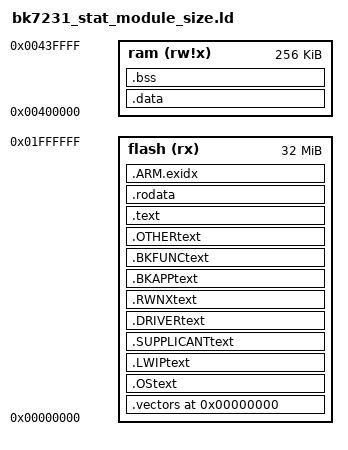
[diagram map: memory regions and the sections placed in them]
/* 
 * Script for GNU linker.
 * Describes layout of sections, location of stack.
 *
 * In this case vectors are at location 0 (reset @ 0x08)
 *
 * +------------+  0x00400000
 * data         |
 * end
 * |(heap)      |
 * .            .
 * .            .
 * |(heap limit)|
 *
 * |- - - - - - |
 * stack bottom    256k
 * +------------+  
 *
 * +------------+  0x0000000
 * |vectors     |
 * |            |
 * |------------+
 * |text        |  
 * |data        |
 * |            |  1024k
 * +------------+
 */


/* Split memory into area for vectors and ram */
MEMORY
{
	flash  (rx) : ORIGIN = 0x00000000, LENGTH = 32M
	ram   (rw!x): ORIGIN = 0x00400000, LENGTH = 256k
}

OUTPUT_FORMAT("elf32-littlearm", "elf32-littlearm", "elf32-littlearm")
OUTPUT_ARCH(arm)
ENTRY(_vector_start);
_vector_start = 0x00000000;

SECTIONS
{
/* vectors go to vectors region */
	. = 0x00000000;
	.vectors : 
	{ 
      KEEP(*(*.vectors))
	} > flash
	
	
	. = ALIGN(0x8);
	.OStext : 
	{
		beken378\os\mem_arch.o(.text)
		beken378\os\str_arch.o(.text)
		beken378\os\str_arch.o(.text.*)
		beken378\os\FreeRTOSv9.0.0\rtos_pub.o(.text)
		beken378\os\FreeRTOSv9.0.0\rtos_pub.o(.text.*)
		FreeRTOSv9.0.0\FreeRTOS\Source\croutine.o(.text)
		FreeRTOSv9.0.0\FreeRTOS\Source\croutine.o(.text.*)
		FreeRTOSv9.0.0\FreeRTOS\Source\event_groups.o(.text)
		FreeRTOSv9.0.0\FreeRTOS\Source\event_groups.o(.text.*)
		FreeRTOSv9.0.0\FreeRTOS\Source\list.o(.text)
		FreeRTOSv9.0.0\FreeRTOS\Source\list.o(.text.*)
		FreeRTOSv9.0.0\FreeRTOS\Source\queue.o(.text)
		FreeRTOSv9.0.0\FreeRTOS\Source\queue.o(.text.*)
		FreeRTOSv9.0.0\FreeRTOS\Source\tasks.o(.text)
		FreeRTOSv9.0.0\FreeRTOS\Source\tasks.o(.text.*)
		FreeRTOSv9.0.0\FreeRTOS\Source\timers.o(.text)
		FreeRTOSv9.0.0\FreeRTOS\Source\timers.o(.text.*)
		FreeRTOSv9.0.0\FreeRTOS\Source\portable\Keil\ARM968es\port.o(.text)
		FreeRTOSv9.0.0\FreeRTOS\Source\portable\Keil\ARM968es\port.o(.text.*)
		FreeRTOSv9.0.0\FreeRTOS\Source\portable\MemMang\heap_4.o(.text)
		FreeRTOSv9.0.0\FreeRTOS\Source\portable\MemMang\heap_4.o(.text.*)
	} > flash

	. = ALIGN(0x8);
	.LWIPtext : 
	{
		beken378\func\lwip_intf\lwip-2.0.2\port\ethernetif.o(.text)
		beken378\func\lwip_intf\lwip-2.0.2\port\net.o(.text)
		beken378\func\lwip_intf\lwip-2.0.2\port\sys_arch.o(.text)
		beken378\func\lwip_intf\lwip-2.0.2\src\api\api_lib.o(.text)
		beken378\func\lwip_intf\lwip-2.0.2\src\api\api_msg.o(.text)
		beken378\func\lwip_intf\lwip-2.0.2\src\api\err.o(.text)
		beken378\func\lwip_intf\lwip-2.0.2\src\api\netbuf.o(.text)
		beken378\func\lwip_intf\lwip-2.0.2\src\api\netdb.o(.text)
		beken378\func\lwip_intf\lwip-2.0.2\src\api\netifapi.o(.text)
		beken378\func\lwip_intf\lwip-2.0.2\src\api\sockets.o(.text)
		beken378\func\lwip_intf\lwip-2.0.2\src\api\tcpip.o(.text)
		beken378\func\lwip_intf\lwip-2.0.2\src\core\def.o(.text)
		beken378\func\lwip_intf\lwip-2.0.2\src\core\dns.o(.text)
		beken378\func\lwip_intf\lwip-2.0.2\src\core\inet_chksum.o(.text)
		beken378\func\lwip_intf\lwip-2.0.2\src\core\init.o(.text)
		beken378\func\lwip_intf\lwip-2.0.2\src\core\ip.o(.text)
		beken378\func\lwip_intf\lwip-2.0.2\src\core\mem.o(.text)
		beken378\func\lwip_intf\lwip-2.0.2\src\core\memp.o(.text)
		beken378\func\lwip_intf\lwip-2.0.2\src\core\netif.o(.text)
		beken378\func\lwip_intf\lwip-2.0.2\src\core\pbuf.o(.text)
		beken378\func\lwip_intf\lwip-2.0.2\src\core\raw.o(.text)
		beken378\func\lwip_intf\lwip-2.0.2\src\core\stats.o(.text)
		beken378\func\lwip_intf\lwip-2.0.2\src\core\sys.o(.text)
		beken378\func\lwip_intf\lwip-2.0.2\src\core\tcp.o(.text)
		beken378\func\lwip_intf\lwip-2.0.2\src\core\tcp_in.o(.text)
		beken378\func\lwip_intf\lwip-2.0.2\src\core\tcp_out.o(.text)
		beken378\func\lwip_intf\lwip-2.0.2\src\core\timeouts.o(.text)
		beken378\func\lwip_intf\lwip-2.0.2\src\core\udp.o(.text)
		beken378\func\lwip_intf\lwip-2.0.2\src\core\ipv4\autoip.o(.text)
		beken378\func\lwip_intf\lwip-2.0.2\src\core\ipv4\dhcp.o(.text)
		beken378\func\lwip_intf\lwip-2.0.2\src\core\ipv4\etharp.o(.text)
		beken378\func\lwip_intf\lwip-2.0.2\src\core\ipv4\icmp.o(.text)
		beken378\func\lwip_intf\lwip-2.0.2\src\core\ipv4\igmp.o(.text)
		beken378\func\lwip_intf\lwip-2.0.2\src\core\ipv4\ip4.o(.text)
		beken378\func\lwip_intf\lwip-2.0.2\src\core\ipv4\ip4_addr.o(.text)
		beken378\func\lwip_intf\lwip-2.0.2\src\core\ipv4\ip4_frag.o(.text)
		beken378\func\lwip_intf\lwip-2.0.2\src\core\ipv6\dhcp6.o(.text)
		beken378\func\lwip_intf\lwip-2.0.2\src\core\ipv6\ethip6.o(.text)
		beken378\func\lwip_intf\lwip-2.0.2\src\core\ipv6\icmp6.o(.text)
		beken378\func\lwip_intf\lwip-2.0.2\src\core\ipv6\inet6.o(.text)
		beken378\func\lwip_intf\lwip-2.0.2\src\core\ipv6\ip6.o(.text)
		beken378\func\lwip_intf\lwip-2.0.2\src\core\ipv6\ip6_addr.o(.text)
		beken378\func\lwip_intf\lwip-2.0.2\src\core\ipv6\ip6_frag.o(.text)
		beken378\func\lwip_intf\lwip-2.0.2\src\core\ipv6\mld6.o(.text)
		beken378\func\lwip_intf\lwip-2.0.2\src\core\ipv6\nd6.o(.text)
		beken378\func\lwip_intf\lwip-2.0.2\src\netif\ethernet.o(.text)
		beken378\func\lwip_intf\lwip-2.0.2\src\netif\lowpan6.o(.text)
		beken378\func\lwip_intf\lwip-2.0.2\src\netif\ppp\auth.o(.text)
		beken378\func\lwip_intf\lwip-2.0.2\src\netif\ppp\ccp.o(.text)
		beken378\func\lwip_intf\lwip-2.0.2\src\netif\ppp\chap-md5.o(.text)
		beken378\func\lwip_intf\lwip-2.0.2\src\netif\ppp\chap-new.o(.text)
		beken378\func\lwip_intf\lwip-2.0.2\src\netif\ppp\chap_ms.o(.text)
		beken378\func\lwip_intf\lwip-2.0.2\src\netif\ppp\demand.o(.text)
		beken378\func\lwip_intf\lwip-2.0.2\src\netif\ppp\eap.o(.text)
		beken378\func\lwip_intf\lwip-2.0.2\src\netif\ppp\ecp.o(.text)
		beken378\func\lwip_intf\lwip-2.0.2\src\netif\ppp\eui64.o(.text)
		beken378\func\lwip_intf\lwip-2.0.2\src\netif\ppp\fsm.o(.text)
		beken378\func\lwip_intf\lwip-2.0.2\src\netif\ppp\ipcp.o(.text)
		beken378\func\lwip_intf\lwip-2.0.2\src\netif\ppp\ipv6cp.o(.text)
		beken378\func\lwip_intf\lwip-2.0.2\src\netif\ppp\lcp.o(.text)
		beken378\func\lwip_intf\lwip-2.0.2\src\netif\ppp\magic.o(.text)
		beken378\func\lwip_intf\lwip-2.0.2\src\netif\ppp\mppe.o(.text)
		beken378\func\lwip_intf\lwip-2.0.2\src\netif\ppp\multilink.o(.text)
		beken378\func\lwip_intf\lwip-2.0.2\src\netif\ppp\ppp.o(.text)
		beken378\func\lwip_intf\lwip-2.0.2\src\netif\ppp\pppapi.o(.text)
		beken378\func\lwip_intf\lwip-2.0.2\src\netif\ppp\pppcrypt.o(.text)
		beken378\func\lwip_intf\lwip-2.0.2\src\netif\ppp\pppoe.o(.text)
		beken378\func\lwip_intf\lwip-2.0.2\src\netif\ppp\pppol2tp.o(.text)
		beken378\func\lwip_intf\lwip-2.0.2\src\netif\ppp\pppos.o(.text)
		beken378\func\lwip_intf\lwip-2.0.2\src\netif\ppp\upap.o(.text)
		beken378\func\lwip_intf\lwip-2.0.2\src\netif\ppp\utils.o(.text)
		beken378\func\lwip_intf\lwip-2.0.2\src\netif\ppp\vj.o(.text)
		beken378\func\lwip_intf\lwip-2.0.2\src\netif\ppp\polarssl\arc4.o(.text)
		beken378\func\lwip_intf\lwip-2.0.2\src\netif\ppp\polarssl\des.o(.text)
		beken378\func\lwip_intf\lwip-2.0.2\src\netif\ppp\polarssl\md4.o(.text)
		beken378\func\lwip_intf\lwip-2.0.2\src\netif\ppp\polarssl\md5.o(.text)
		beken378\func\lwip_intf\lwip-2.0.2\src\netif\ppp\polarssl\sha1.o(.text)
		beken378\func\lwip_intf\lwip-2.0.2\port\ethernetif.o(.text.*)
		beken378\func\lwip_intf\lwip-2.0.2\port\net.o(.text.*)
		beken378\func\lwip_intf\lwip-2.0.2\port\sys_arch.o(.text.*)
		beken378\func\lwip_intf\lwip-2.0.2\src\api\api_lib.o(.text.*)
		beken378\func\lwip_intf\lwip-2.0.2\src\api\api_msg.o(.text.*)
		beken378\func\lwip_intf\lwip-2.0.2\src\api\err.o(.text.*)
		beken378\func\lwip_intf\lwip-2.0.2\src\api\netbuf.o(.text.*)
		beken378\func\lwip_intf\lwip-2.0.2\src\api\netdb.o(.text.*)
		beken378\func\lwip_intf\lwip-2.0.2\src\api\netifapi.o(.text.*)
		beken378\func\lwip_intf\lwip-2.0.2\src\api\sockets.o(.text.*)
		beken378\func\lwip_intf\lwip-2.0.2\src\api\tcpip.o(.text.*)
		beken378\func\lwip_intf\lwip-2.0.2\src\core\def.o(.text.*)
		beken378\func\lwip_intf\lwip-2.0.2\src\core\dns.o(.text.*)
		beken378\func\lwip_intf\lwip-2.0.2\src\core\inet_chksum.o(.text.*)
		beken378\func\lwip_intf\lwip-2.0.2\src\core\init.o(.text.*)
		beken378\func\lwip_intf\lwip-2.0.2\src\core\ip.o(.text.*)
		beken378\func\lwip_intf\lwip-2.0.2\src\core\mem.o(.text.*)
		beken378\func\lwip_intf\lwip-2.0.2\src\core\memp.o(.text.*)
		beken378\func\lwip_intf\lwip-2.0.2\src\core\netif.o(.text.*)
		beken378\func\lwip_intf\lwip-2.0.2\src\core\pbuf.o(.text.*)
		beken378\func\lwip_intf\lwip-2.0.2\src\core\raw.o(.text.*)
		beken378\func\lwip_intf\lwip-2.0.2\src\core\stats.o(.text.*)
		beken378\func\lwip_intf\lwip-2.0.2\src\core\sys.o(.text.*)
		beken378\func\lwip_intf\lwip-2.0.2\src\core\tcp.o(.text.*)
		beken378\func\lwip_intf\lwip-2.0.2\src\core\tcp_in.o(.text.*)
		beken378\func\lwip_intf\lwip-2.0.2\src\core\tcp_out.o(.text.*)
		beken378\func\lwip_intf\lwip-2.0.2\src\core\timeouts.o(.text.*)
		beken378\func\lwip_intf\lwip-2.0.2\src\core\udp.o(.text.*)
		beken378\func\lwip_intf\lwip-2.0.2\src\core\ipv4\autoip.o(.text.*)
		beken378\func\lwip_intf\lwip-2.0.2\src\core\ipv4\dhcp.o(.text.*)
		beken378\func\lwip_intf\lwip-2.0.2\src\core\ipv4\etharp.o(.text.*)
		beken378\func\lwip_intf\lwip-2.0.2\src\core\ipv4\icmp.o(.text.*)
		beken378\func\lwip_intf\lwip-2.0.2\src\core\ipv4\igmp.o(.text.*)
		beken378\func\lwip_intf\lwip-2.0.2\src\core\ipv4\ip4.o(.text.*)
		beken378\func\lwip_intf\lwip-2.0.2\src\core\ipv4\ip4_addr.o(.text.*)
		beken378\func\lwip_intf\lwip-2.0.2\src\core\ipv4\ip4_frag.o(.text.*)
		beken378\func\lwip_intf\lwip-2.0.2\src\core\ipv6\dhcp6.o(.text.*)
		beken378\func\lwip_intf\lwip-2.0.2\src\core\ipv6\ethip6.o(.text.*)
		beken378\func\lwip_intf\lwip-2.0.2\src\core\ipv6\icmp6.o(.text.*)
		beken378\func\lwip_intf\lwip-2.0.2\src\core\ipv6\inet6.o(.text.*)
		beken378\func\lwip_intf\lwip-2.0.2\src\core\ipv6\ip6.o(.text.*)
		beken378\func\lwip_intf\lwip-2.0.2\src\core\ipv6\ip6_addr.o(.text.*)
		beken378\func\lwip_intf\lwip-2.0.2\src\core\ipv6\ip6_frag.o(.text.*)
		beken378\func\lwip_intf\lwip-2.0.2\src\core\ipv6\mld6.o(.text.*)
		beken378\func\lwip_intf\lwip-2.0.2\src\core\ipv6\nd6.o(.text.*)
		beken378\func\lwip_intf\lwip-2.0.2\src\netif\ethernet.o(.text.*)
		beken378\func\lwip_intf\lwip-2.0.2\src\netif\lowpan6.o(.text.*)
		beken378\func\lwip_intf\lwip-2.0.2\src\netif\ppp\auth.o(.text.*)
		beken378\func\lwip_intf\lwip-2.0.2\src\netif\ppp\ccp.o(.text.*)
		beken378\func\lwip_intf\lwip-2.0.2\src\netif\ppp\chap-md5.o(.text.*)
		beken378\func\lwip_intf\lwip-2.0.2\src\netif\ppp\chap-new.o(.text.*)
		beken378\func\lwip_intf\lwip-2.0.2\src\netif\ppp\chap_ms.o(.text.*)
		beken378\func\lwip_intf\lwip-2.0.2\src\netif\ppp\demand.o(.text.*)
		beken378\func\lwip_intf\lwip-2.0.2\src\netif\ppp\eap.o(.text.*)
		beken378\func\lwip_intf\lwip-2.0.2\src\netif\ppp\ecp.o(.text.*)
		beken378\func\lwip_intf\lwip-2.0.2\src\netif\ppp\eui64.o(.text.*)
		beken378\func\lwip_intf\lwip-2.0.2\src\netif\ppp\fsm.o(.text.*)
		beken378\func\lwip_intf\lwip-2.0.2\src\netif\ppp\ipcp.o(.text.*)
		beken378\func\lwip_intf\lwip-2.0.2\src\netif\ppp\ipv6cp.o(.text.*)
		beken378\func\lwip_intf\lwip-2.0.2\src\netif\ppp\lcp.o(.text.*)
		beken378\func\lwip_intf\lwip-2.0.2\src\netif\ppp\magic.o(.text.*)
		beken378\func\lwip_intf\lwip-2.0.2\src\netif\ppp\mppe.o(.text.*)
		beken378\func\lwip_intf\lwip-2.0.2\src\netif\ppp\multilink.o(.text.*)
		beken378\func\lwip_intf\lwip-2.0.2\src\netif\ppp\ppp.o(.text.*)
		beken378\func\lwip_intf\lwip-2.0.2\src\netif\ppp\pppapi.o(.text.*)
		beken378\func\lwip_intf\lwip-2.0.2\src\netif\ppp\pppcrypt.o(.text.*)
		beken378\func\lwip_intf\lwip-2.0.2\src\netif\ppp\pppoe.o(.text.*)
		beken378\func\lwip_intf\lwip-2.0.2\src\netif\ppp\pppol2tp.o(.text.*)
		beken378\func\lwip_intf\lwip-2.0.2\src\netif\ppp\pppos.o(.text.*)
		beken378\func\lwip_intf\lwip-2.0.2\src\netif\ppp\upap.o(.text.*)
		beken378\func\lwip_intf\lwip-2.0.2\src\netif\ppp\utils.o(.text.*)
		beken378\func\lwip_intf\lwip-2.0.2\src\netif\ppp\vj.o(.text.*)
		beken378\func\lwip_intf\lwip-2.0.2\src\netif\ppp\polarssl\arc4.o(.text.*)
		beken378\func\lwip_intf\lwip-2.0.2\src\netif\ppp\polarssl\des.o(.text.*)
		beken378\func\lwip_intf\lwip-2.0.2\src\netif\ppp\polarssl\md4.o(.text.*)
		beken378\func\lwip_intf\lwip-2.0.2\src\netif\ppp\polarssl\md5.o(.text.*)
		beken378\func\lwip_intf\lwip-2.0.2\src\netif\ppp\polarssl\sha1.o(.text.*)
	} > flash
	
	. = ALIGN(0x8);
	.SUPPLICANTtext : 
	{		
		beken378\func\hostapd-2.5\bk_patch\ddrv.o(.text)
		beken378\func\hostapd-2.5\bk_patch\fake_socket.o(.text)
		beken378\func\hostapd-2.5\bk_patch\signal.o(.text)
		beken378\func\hostapd-2.5\bk_patch\sk_intf.o(.text)
		beken378\func\hostapd-2.5\hostapd\main_none.o(.text)
		beken378\func\hostapd-2.5\src\ap\ap_config.o(.text)
		beken378\func\hostapd-2.5\src\ap\ap_drv_ops.o(.text)
		beken378\func\hostapd-2.5\src\ap\ap_list.o(.text)
		beken378\func\hostapd-2.5\src\ap\ap_mlme.o(.text)
		beken378\func\hostapd-2.5\src\ap\authsrv.o(.text)
		beken378\func\hostapd-2.5\src\ap\beacon.o(.text)
		beken378\func\hostapd-2.5\src\ap\bss_load.o(.text)
		beken378\func\hostapd-2.5\src\ap\dfs.o(.text)
		beken378\func\hostapd-2.5\src\ap\drv_callbacks.o(.text)
		beken378\func\hostapd-2.5\src\ap\eap_user_db.o(.text)
		beken378\func\hostapd-2.5\src\ap\hostapd.o(.text)
		beken378\func\hostapd-2.5\src\ap\hw_features.o(.text)
		beken378\func\hostapd-2.5\src\ap\ieee802_11.o(.text)
		beken378\func\hostapd-2.5\src\ap\ieee802_11_auth.o(.text)
		beken378\func\hostapd-2.5\src\ap\ieee802_11_ht.o(.text)
		beken378\func\hostapd-2.5\src\ap\ieee802_11_shared.o(.text)
		beken378\func\hostapd-2.5\src\ap\ieee802_1x.o(.text)
		beken378\func\hostapd-2.5\src\ap\pmksa_cache_auth.o(.text)
		beken378\func\hostapd-2.5\src\ap\sta_info.o(.text)
		beken378\func\hostapd-2.5\src\ap\tkip_countermeasures.o(.text)
		beken378\func\hostapd-2.5\src\ap\utils.o(.text)
		beken378\func\hostapd-2.5\src\ap\wmm.o(.text)
		beken378\func\hostapd-2.5\src\ap\wpa_auth.o(.text)
		beken378\func\hostapd-2.5\src\ap\wpa_auth_glue.o(.text)
		beken378\func\hostapd-2.5\src\ap\wpa_auth_ie.o(.text)
		beken378\func\hostapd-2.5\src\common\hw_features_common.o(.text)
		beken378\func\hostapd-2.5\src\common\ieee802_11_common.o(.text)
		beken378\func\hostapd-2.5\src\common\wpa_common.o(.text)
		beken378\func\hostapd-2.5\src\crypto\aes-internal-dec.o(.text)
		beken378\func\hostapd-2.5\src\crypto\aes-internal-enc.o(.text)
		beken378\func\hostapd-2.5\src\crypto\aes-internal.o(.text)
		beken378\func\hostapd-2.5\src\crypto\aes-unwrap.o(.text)
		beken378\func\hostapd-2.5\src\crypto\aes-wrap.o(.text)
		beken378\func\hostapd-2.5\src\crypto\md5-internal.o(.text)
		beken378\func\hostapd-2.5\src\crypto\md5.o(.text)
		beken378\func\hostapd-2.5\src\crypto\rc4.o(.text)
		beken378\func\hostapd-2.5\src\crypto\sha1-internal.o(.text)
		beken378\func\hostapd-2.5\src\crypto\sha1-pbkdf2.o(.text)
		beken378\func\hostapd-2.5\src\crypto\sha1-prf.o(.text)
		beken378\func\hostapd-2.5\src\crypto\sha1.o(.text)
		beken378\func\hostapd-2.5\src\crypto\tls_none.o(.text)
		beken378\func\hostapd-2.5\src\drivers\drivers.o(.text)
		beken378\func\hostapd-2.5\src\drivers\driver_beken.o(.text)
		beken378\func\hostapd-2.5\src\drivers\driver_common.o(.text)
		beken378\func\hostapd-2.5\src\eapol_auth\eapol_auth_sm.o(.text)
		beken378\func\hostapd-2.5\src\eap_common\eap_common.o(.text)
		beken378\func\hostapd-2.5\src\eap_server\eap_server.o(.text)
		beken378\func\hostapd-2.5\src\eap_server\eap_server_methods.o(.text)
		beken378\func\hostapd-2.5\src\l2_packet\l2_packet_none.o(.text)
		beken378\func\hostapd-2.5\src\rsn_supp\preauth.o(.text)
		beken378\func\hostapd-2.5\src\rsn_supp\wpa.o(.text)
		beken378\func\hostapd-2.5\src\rsn_supp\wpa_ie.o(.text)
		beken378\func\hostapd-2.5\src\utils\common.o(.text)
		beken378\func\hostapd-2.5\src\utils\eloop.o(.text)
		beken378\func\hostapd-2.5\src\utils\os_none.o(.text)
		beken378\func\hostapd-2.5\src\utils\wpabuf.o(.text)
		beken378\func\hostapd-2.5\wpa_supplicant\ap.o(.text)
		beken378\func\hostapd-2.5\wpa_supplicant\blacklist.o(.text)
		beken378\func\hostapd-2.5\wpa_supplicant\bss.o(.text)
		beken378\func\hostapd-2.5\wpa_supplicant\config.o(.text)
		beken378\func\hostapd-2.5\wpa_supplicant\config_none.o(.text)
		beken378\func\hostapd-2.5\wpa_supplicant\eap_register.o(.text)
		beken378\func\hostapd-2.5\wpa_supplicant\events.o(.text)
		beken378\func\hostapd-2.5\wpa_supplicant\main_supplicant.o(.text)
		beken378\func\hostapd-2.5\wpa_supplicant\notify.o(.text)
		beken378\func\hostapd-2.5\wpa_supplicant\wmm_ac.o(.text)
		beken378\func\hostapd-2.5\wpa_supplicant\wpas_glue.o(.text)
		beken378\func\hostapd-2.5\wpa_supplicant\wpa_scan.o(.text)
		beken378\func\hostapd-2.5\wpa_supplicant\wpa_supplicant.o(.text)		
		beken378\func\hostapd-2.5\bk_patch\ddrv.o(.text.*)
		beken378\func\hostapd-2.5\bk_patch\fake_socket.o(.text.*)
		beken378\func\hostapd-2.5\bk_patch\signal.o(.text.*)
		beken378\func\hostapd-2.5\bk_patch\sk_intf.o(.text.*)
		beken378\func\hostapd-2.5\hostapd\main_none.o(.text.*)
		beken378\func\hostapd-2.5\src\ap\ap_config.o(.text.*)
		beken378\func\hostapd-2.5\src\ap\ap_drv_ops.o(.text.*)
		beken378\func\hostapd-2.5\src\ap\ap_list.o(.text.*)
		beken378\func\hostapd-2.5\src\ap\ap_mlme.o(.text.*)
		beken378\func\hostapd-2.5\src\ap\authsrv.o(.text.*)
		beken378\func\hostapd-2.5\src\ap\beacon.o(.text.*)
		beken378\func\hostapd-2.5\src\ap\bss_load.o(.text.*)
		beken378\func\hostapd-2.5\src\ap\dfs.o(.text.*)
		beken378\func\hostapd-2.5\src\ap\drv_callbacks.o(.text.*)
		beken378\func\hostapd-2.5\src\ap\eap_user_db.o(.text.*)
		beken378\func\hostapd-2.5\src\ap\hostapd.o(.text.*)
		beken378\func\hostapd-2.5\src\ap\hw_features.o(.text.*)
		beken378\func\hostapd-2.5\src\ap\ieee802_11.o(.text.*)
		beken378\func\hostapd-2.5\src\ap\ieee802_11_auth.o(.text.*)
		beken378\func\hostapd-2.5\src\ap\ieee802_11_ht.o(.text.*)
		beken378\func\hostapd-2.5\src\ap\ieee802_11_shared.o(.text.*)
		beken378\func\hostapd-2.5\src\ap\ieee802_1x.o(.text.*)
		beken378\func\hostapd-2.5\src\ap\pmksa_cache_auth.o(.text.*)
		beken378\func\hostapd-2.5\src\ap\sta_info.o(.text.*)
		beken378\func\hostapd-2.5\src\ap\tkip_countermeasures.o(.text.*)
		beken378\func\hostapd-2.5\src\ap\utils.o(.text.*)
		beken378\func\hostapd-2.5\src\ap\wmm.o(.text.*)
		beken378\func\hostapd-2.5\src\ap\wpa_auth.o(.text.*)
		beken378\func\hostapd-2.5\src\ap\wpa_auth_glue.o(.text.*)
		beken378\func\hostapd-2.5\src\ap\wpa_auth_ie.o(.text.*)
		beken378\func\hostapd-2.5\src\common\hw_features_common.o(.text.*)
		beken378\func\hostapd-2.5\src\common\ieee802_11_common.o(.text.*)
		beken378\func\hostapd-2.5\src\common\wpa_common.o(.text.*)
		beken378\func\hostapd-2.5\src\crypto\aes-internal-dec.o(.text.*)
		beken378\func\hostapd-2.5\src\crypto\aes-internal-enc.o(.text.*)
		beken378\func\hostapd-2.5\src\crypto\aes-internal.o(.text.*)
		beken378\func\hostapd-2.5\src\crypto\aes-unwrap.o(.text.*)
		beken378\func\hostapd-2.5\src\crypto\aes-wrap.o(.text.*)
		beken378\func\hostapd-2.5\src\crypto\md5-internal.o(.text.*)
		beken378\func\hostapd-2.5\src\crypto\md5.o(.text.*)
		beken378\func\hostapd-2.5\src\crypto\rc4.o(.text.*)
		beken378\func\hostapd-2.5\src\crypto\sha1-internal.o(.text.*)
		beken378\func\hostapd-2.5\src\crypto\sha1-pbkdf2.o(.text.*)
		beken378\func\hostapd-2.5\src\crypto\sha1-prf.o(.text.*)
		beken378\func\hostapd-2.5\src\crypto\sha1.o(.text.*)
		beken378\func\hostapd-2.5\src\crypto\tls_none.o(.text.*)
		beken378\func\hostapd-2.5\src\drivers\drivers.o(.text.*)
		beken378\func\hostapd-2.5\src\drivers\driver_beken.o(.text.*)
		beken378\func\hostapd-2.5\src\drivers\driver_common.o(.text.*)
		beken378\func\hostapd-2.5\src\eapol_auth\eapol_auth_sm.o(.text.*)
		beken378\func\hostapd-2.5\src\eap_common\eap_common.o(.text.*)
		beken378\func\hostapd-2.5\src\eap_server\eap_server.o(.text.*)
		beken378\func\hostapd-2.5\src\eap_server\eap_server_methods.o(.text.*)
		beken378\func\hostapd-2.5\src\l2_packet\l2_packet_none.o(.text.*)
		beken378\func\hostapd-2.5\src\rsn_supp\preauth.o(.text.*)
		beken378\func\hostapd-2.5\src\rsn_supp\wpa.o(.text.*)
		beken378\func\hostapd-2.5\src\rsn_supp\wpa_ie.o(.text.*)
		beken378\func\hostapd-2.5\src\utils\common.o(.text.*)
		beken378\func\hostapd-2.5\src\utils\eloop.o(.text.*)
		beken378\func\hostapd-2.5\src\utils\os_none.o(.text.*)
		beken378\func\hostapd-2.5\src\utils\wpabuf.o(.text.*)
		beken378\func\hostapd-2.5\wpa_supplicant\ap.o(.text.*)
		beken378\func\hostapd-2.5\wpa_supplicant\blacklist.o(.text.*)
		beken378\func\hostapd-2.5\wpa_supplicant\bss.o(.text.*)
		beken378\func\hostapd-2.5\wpa_supplicant\config.o(.text.*)
		beken378\func\hostapd-2.5\wpa_supplicant\config_none.o(.text.*)
		beken378\func\hostapd-2.5\wpa_supplicant\eap_register.o(.text.*)
		beken378\func\hostapd-2.5\wpa_supplicant\events.o(.text.*)
		beken378\func\hostapd-2.5\wpa_supplicant\main_supplicant.o(.text.*)
		beken378\func\hostapd-2.5\wpa_supplicant\notify.o(.text.*)
		beken378\func\hostapd-2.5\wpa_supplicant\wmm_ac.o(.text.*)
		beken378\func\hostapd-2.5\wpa_supplicant\wpas_glue.o(.text.*)
		beken378\func\hostapd-2.5\wpa_supplicant\wpa_scan.o(.text.*)
		beken378\func\hostapd-2.5\wpa_supplicant\wpa_supplicant.o(.text.*)
	} > flash
	
	. = ALIGN(0x8);
	.DRIVERtext : 
	{		
		beken378\driver\driver.o(.text)
		beken378\driver\audio\audio.o(.text)
		beken378\driver\audio\audio_adc.o(.text)
		beken378\driver\audio\audio_dac.o(.text)
		beken378\driver\audio\ring_buffer.o(.text)
		beken378\driver\audio\ring_buffer_dma_read.o(.text)
		beken378\driver\audio\ring_buffer_dma_write.o(.text)
		beken378\driver\codec\driver_codec_es8374.o(.text)
		beken378\driver\common\dd.o(.text)
		beken378\driver\common\drv_model.o(.text)
		beken378\driver\dma\dma.o(.text)
		beken378\driver\entry\arch_main.o(.text)
		beken378\driver\fft\fft.o(.text)
		beken378\driver\flash\flash.o(.text)
		beken378\driver\general_dma\general_dma.o(.text)
		beken378\driver\gpio\gpio.o(.text)
		beken378\driver\i2c\i2c1.o(.text)
		beken378\driver\i2c\i2c2.o(.text)
		beken378\driver\i2s\i2s.o(.text)
		beken378\driver\icu\icu.o(.text)
		beken378\driver\intc\intc.o(.text)
		beken378\driver\irda\irda.o(.text)
		beken378\driver\jpeg\jpeg_encoder.o(.text)
		beken378\driver\macphy_bypass\mac_phy_bypass.o(.text)
		beken378\driver\phy\phy_trident.o(.text)
		beken378\driver\pwm\bk_timer.o(.text)
		beken378\driver\pwm\mcu_ps_timer.o(.text)
		beken378\driver\pwm\pwm.o(.text)
		beken378\driver\rw_pub\rw_platf_pub.o(.text)
		beken378\driver\saradc\saradc.o(.text)
		beken378\driver\sdcard\sdcard.o(.text)
		beken378\driver\sdcard\sdio_driver.o(.text)
		beken378\driver\sdio\sdio.o(.text)
		beken378\driver\sdio\sdma.o(.text)
		beken378\driver\sdio\sutil.o(.text)
		beken378\driver\spi\spi.o(.text)
		beken378\driver\spidma\spidma.o(.text)
		beken378\driver\sys_ctrl\sys_ctrl.o(.text)
		beken378\driver\uart\Retarget.o(.text)
		beken378\driver\uart\uart.o(.text)
		beken378\driver\wdt\wdt.o(.text)		
		beken378\driver\driver.o(.text.*)
		beken378\driver\audio\audio.o(.text.*)
		beken378\driver\audio\audio_adc.o(.text.*)
		beken378\driver\audio\audio_dac.o(.text.*)
		beken378\driver\audio\ring_buffer.o(.text.*)
		beken378\driver\audio\ring_buffer_dma_read.o(.text.*)
		beken378\driver\audio\ring_buffer_dma_write.o(.text.*)
		beken378\driver\codec\driver_codec_es8374.o(.text.*)
		beken378\driver\common\dd.o(.text.*)
		beken378\driver\common\drv_model.o(.text.*)
		beken378\driver\dma\dma.o(.text.*)
		beken378\driver\entry\arch_main.o(.text.*)
		beken378\driver\fft\fft.o(.text.*)
		beken378\driver\flash\flash.o(.text.*)
		beken378\driver\general_dma\general_dma.o(.text.*)
		beken378\driver\gpio\gpio.o(.text.*)
		beken378\driver\i2c\i2c1.o(.text.*)
		beken378\driver\i2c\i2c2.o(.text.*)
		beken378\driver\i2s\i2s.o(.text.*)
		beken378\driver\icu\icu.o(.text.*)
		beken378\driver\intc\intc.o(.text.*)
		beken378\driver\irda\irda.o(.text.*)
		beken378\driver\jpeg\jpeg_encoder.o(.text.*)
		beken378\driver\macphy_bypass\mac_phy_bypass.o(.text.*)
		beken378\driver\phy\phy_trident.o(.text.*)
		beken378\driver\pwm\bk_timer.o(.text.*)
		beken378\driver\pwm\mcu_ps_timer.o(.text.*)
		beken378\driver\pwm\pwm.o(.text.*)
		beken378\driver\rw_pub\rw_platf_pub.o(.text.*)
		beken378\driver\saradc\saradc.o(.text.*)
		beken378\driver\sdcard\sdcard.o(.text.*)
		beken378\driver\sdcard\sdio_driver.o(.text.*)
		beken378\driver\sdio\sdio.o(.text.*)
		beken378\driver\sdio\sdma.o(.text.*)
		beken378\driver\sdio\sutil.o(.text.*)
		beken378\driver\spi\spi.o(.text.*)
		beken378\driver\spidma\spidma.o(.text.*)
		beken378\driver\sys_ctrl\sys_ctrl.o(.text.*)
		beken378\driver\uart\Retarget.o(.text.*)
		beken378\driver\uart\uart.o(.text.*)
		beken378\driver\wdt\wdt.o(.text.*)
	} > flash
	
	. = ALIGN(0x8);
	.RWNXtext : 
	{		
		beken378\ip\common\co_dlist.o(.text)
		beken378\ip\common\co_list.o(.text)
		beken378\ip\common\co_math.o(.text)
		beken378\ip\common\co_pool.o(.text)
		beken378\ip\common\co_ring.o(.text)
		beken378\ip\ke\ke_env.o(.text)
		beken378\ip\ke\ke_event.o(.text)
		beken378\ip\ke\ke_msg.o(.text)
		beken378\ip\ke\ke_queue.o(.text)
		beken378\ip\ke\ke_task.o(.text)
		beken378\ip\ke\ke_timer.o(.text)
		beken378\ip\lmac\src\chan\chan.o(.text)
		beken378\ip\lmac\src\hal\hal_desc.o(.text)
		beken378\ip\lmac\src\hal\hal_dma.o(.text)
		beken378\ip\lmac\src\hal\hal_machw.o(.text)
		beken378\ip\lmac\src\hal\hal_mib.o(.text)
		beken378\ip\lmac\src\mm\mm.o(.text)
		beken378\ip\lmac\src\mm\mm_bcn.o(.text)
		beken378\ip\lmac\src\mm\mm_task.o(.text)
		beken378\ip\lmac\src\mm\mm_timer.o(.text)
		beken378\ip\lmac\src\p2p\p2p.o(.text)
		beken378\ip\lmac\src\ps\ps.o(.text)
		beken378\ip\lmac\src\rd\rd.o(.text)
		beken378\ip\lmac\src\rwnx\rwnx.o(.text)
		beken378\ip\lmac\src\rx\rx_swdesc.o(.text)
		beken378\ip\lmac\src\rx\rxl\rxl_cntrl.o(.text)
		beken378\ip\lmac\src\rx\rxl\rxl_hwdesc.o(.text)
		beken378\ip\lmac\src\scan\scan.o(.text)
		beken378\ip\lmac\src\scan\scan_shared.o(.text)
		beken378\ip\lmac\src\scan\scan_task.o(.text)
		beken378\ip\lmac\src\sta\sta_mgmt.o(.text)
		beken378\ip\lmac\src\td\td.o(.text)
		beken378\ip\lmac\src\tdls\tdls.o(.text)
		beken378\ip\lmac\src\tdls\tdls_task.o(.text)
		beken378\ip\lmac\src\tpc\tpc.o(.text)
		beken378\ip\lmac\src\tx\tx_swdesc.o(.text)
		beken378\ip\lmac\src\tx\txl\txl_buffer.o(.text)
		beken378\ip\lmac\src\tx\txl\txl_buffer_shared.o(.text)
		beken378\ip\lmac\src\tx\txl\txl_cfm.o(.text)
		beken378\ip\lmac\src\tx\txl\txl_cntrl.o(.text)
		beken378\ip\lmac\src\tx\txl\txl_frame.o(.text)
		beken378\ip\lmac\src\tx\txl\txl_frame_shared.o(.text)
		beken378\ip\lmac\src\tx\txl\txl_hwdesc.o(.text)
		beken378\ip\lmac\src\vif\vif_mgmt.o(.text)
		beken378\ip\mac\mac.o(.text)
		beken378\ip\mac\mac_ie.o(.text)
		beken378\ip\umac\src\apm\apm.o(.text)
		beken378\ip\umac\src\apm\apm_task.o(.text)
		beken378\ip\umac\src\bam\bam.o(.text)
		beken378\ip\umac\src\bam\bam_task.o(.text)
		beken378\ip\umac\src\me\me.o(.text)
		beken378\ip\umac\src\me\me_mgmtframe.o(.text)
		beken378\ip\umac\src\me\me_mic.o(.text)
		beken378\ip\umac\src\me\me_task.o(.text)
		beken378\ip\umac\src\me\me_utils.o(.text)
		beken378\ip\umac\src\rc\rc.o(.text)
		beken378\ip\umac\src\rc\rc_basic.o(.text)
		beken378\ip\umac\src\rxu\rxu_cntrl.o(.text)
		beken378\ip\umac\src\scanu\scanu.o(.text)
		beken378\ip\umac\src\scanu\scanu_shared.o(.text)
		beken378\ip\umac\src\scanu\scanu_task.o(.text)
		beken378\ip\umac\src\sm\sm.o(.text)
		beken378\ip\umac\src\sm\sm_task.o(.text)
		beken378\ip\umac\src\txu\txu_cntrl.o(.text)		
		beken378\ip\common\co_dlist.o(.text.*)
		beken378\ip\common\co_list.o(.text.*)
		beken378\ip\common\co_math.o(.text.*)
		beken378\ip\common\co_pool.o(.text.*)
		beken378\ip\common\co_ring.o(.text.*)
		beken378\ip\ke\ke_env.o(.text.*)
		beken378\ip\ke\ke_event.o(.text.*)
		beken378\ip\ke\ke_msg.o(.text.*)
		beken378\ip\ke\ke_queue.o(.text.*)
		beken378\ip\ke\ke_task.o(.text.*)
		beken378\ip\ke\ke_timer.o(.text.*)
		beken378\ip\lmac\src\chan\chan.o(.text.*)
		beken378\ip\lmac\src\hal\hal_desc.o(.text.*)
		beken378\ip\lmac\src\hal\hal_dma.o(.text.*)
		beken378\ip\lmac\src\hal\hal_machw.o(.text.*)
		beken378\ip\lmac\src\hal\hal_mib.o(.text.*)
		beken378\ip\lmac\src\mm\mm.o(.text.*)
		beken378\ip\lmac\src\mm\mm_bcn.o(.text.*)
		beken378\ip\lmac\src\mm\mm_task.o(.text.*)
		beken378\ip\lmac\src\mm\mm_timer.o(.text.*)
		beken378\ip\lmac\src\p2p\p2p.o(.text.*)
		beken378\ip\lmac\src\ps\ps.o(.text.*)
		beken378\ip\lmac\src\rd\rd.o(.text.*)
		beken378\ip\lmac\src\rwnx\rwnx.o(.text.*)
		beken378\ip\lmac\src\rx\rx_swdesc.o(.text.*)
		beken378\ip\lmac\src\rx\rxl\rxl_cntrl.o(.text.*)
		beken378\ip\lmac\src\rx\rxl\rxl_hwdesc.o(.text.*)
		beken378\ip\lmac\src\scan\scan.o(.text.*)
		beken378\ip\lmac\src\scan\scan_shared.o(.text.*)
		beken378\ip\lmac\src\scan\scan_task.o(.text.*)
		beken378\ip\lmac\src\sta\sta_mgmt.o(.text.*)
		beken378\ip\lmac\src\td\td.o(.text.*)
		beken378\ip\lmac\src\tdls\tdls.o(.text.*)
		beken378\ip\lmac\src\tdls\tdls_task.o(.text.*)
		beken378\ip\lmac\src\tpc\tpc.o(.text.*)
		beken378\ip\lmac\src\tx\tx_swdesc.o(.text.*)
		beken378\ip\lmac\src\tx\txl\txl_buffer.o(.text.*)
		beken378\ip\lmac\src\tx\txl\txl_buffer_shared.o(.text.*)
		beken378\ip\lmac\src\tx\txl\txl_cfm.o(.text.*)
		beken378\ip\lmac\src\tx\txl\txl_cntrl.o(.text.*)
		beken378\ip\lmac\src\tx\txl\txl_frame.o(.text.*)
		beken378\ip\lmac\src\tx\txl\txl_frame_shared.o(.text.*)
		beken378\ip\lmac\src\tx\txl\txl_hwdesc.o(.text.*)
		beken378\ip\lmac\src\vif\vif_mgmt.o(.text.*)
		beken378\ip\mac\mac.o(.text.*)
		beken378\ip\mac\mac_ie.o(.text.*)
		beken378\ip\umac\src\apm\apm.o(.text.*)
		beken378\ip\umac\src\apm\apm_task.o(.text.*)
		beken378\ip\umac\src\bam\bam.o(.text.*)
		beken378\ip\umac\src\bam\bam_task.o(.text.*)
		beken378\ip\umac\src\me\me.o(.text.*)
		beken378\ip\umac\src\me\me_mgmtframe.o(.text.*)
		beken378\ip\umac\src\me\me_mic.o(.text.*)
		beken378\ip\umac\src\me\me_task.o(.text.*)
		beken378\ip\umac\src\me\me_utils.o(.text.*)
		beken378\ip\umac\src\rc\rc.o(.text.*)
		beken378\ip\umac\src\rc\rc_basic.o(.text.*)
		beken378\ip\umac\src\rxu\rxu_cntrl.o(.text.*)
		beken378\ip\umac\src\scanu\scanu.o(.text.*)
		beken378\ip\umac\src\scanu\scanu_shared.o(.text.*)
		beken378\ip\umac\src\scanu\scanu_task.o(.text.*)
		beken378\ip\umac\src\sm\sm.o(.text.*)
		beken378\ip\umac\src\sm\sm_task.o(.text.*)
		beken378\ip\umac\src\txu\txu_cntrl.o(.text.*)
	} > flash
	
	. = ALIGN(0x8);
	.BKAPPtext : 
	{		
		beken378\app\app.o(.text)
		beken378\app\ate_app.o(.text)
		beken378\app\airkiss\airkiss_main.o(.text)
		beken378\app\config\param_config.o(.text)
		beken378\app\ftp\ftpd.o(.text)
		beken378\app\ftp\vfs.o(.text)
		beken378\app\http\lite-log.o(.text)
		beken378\app\http\utils_httpc.o(.text)
		beken378\app\http\utils_net.o(.text)
		beken378\app\http\utils_timer.o(.text)
		beken378\app\led\app_led.o(.text)
		beken378\app\net_work\app_drone.o(.text)
		beken378\app\net_work\app_lwip_tcp.o(.text)
		beken378\app\net_work\app_lwip_udp.o(.text)
		beken378\app\standalone-ap\sa_ap.o(.text)
		beken378\app\standalone-station\sa_station.o(.text)
		beken378\app\tftp\tftpclient.o(.text)
		beken378\app\app.o(.text.*)
		beken378\app\ate_app.o(.text.*)
		beken378\app\airkiss\airkiss_main.o(.text.*)
		beken378\app\config\param_config.o(.text.*)
		beken378\app\ftp\ftpd.o(.text.*)
		beken378\app\ftp\vfs.o(.text.*)
		beken378\app\http\lite-log.o(.text.*)
		beken378\app\http\utils_httpc.o(.text.*)
		beken378\app\http\utils_net.o(.text.*)
		beken378\app\http\utils_timer.o(.text.*)
		beken378\app\led\app_led.o(.text.*)
		beken378\app\net_work\app_drone.o(.text.*)
		beken378\app\net_work\app_lwip_tcp.o(.text.*)
		beken378\app\net_work\app_lwip_udp.o(.text.*)
		beken378\app\standalone-ap\sa_ap.o(.text.*)
		beken378\app\standalone-station\sa_station.o(.text.*)
		beken378\app\tftp\tftpclient.o(.text.*)
	} > flash
	
	. = ALIGN(0x8);
	.BKFUNCtext : 
	{		
		beken378\func\func.o(.text)
		beken378\func\audio\audio_intf.o(.text)
		beken378\func\bk7011_cal\bk7011_cal.o(.text)
		beken378\func\bk7011_cal\bk7221u_cal.o(.text)
		beken378\func\bk7011_cal\bk7231u_cal.o(.text)
		beken378\func\bk7011_cal\bk7231_cal.o(.text)
		beken378\func\bk7011_cal\manual_cal_bk7231.o(.text)
		beken378\func\bk7011_cal\manual_cal_bk7231u.o(.text)
		beken378\func\camera_intf\camera_inft.o(.text)
		beken378\func\hostapd_intf\hostapd_intf.o(.text)
		beken378\func\joint_up\reconnect_startup.o(.text)
		beken378\func\joint_up\role_launch.o(.text)
		beken378\func\key\key_main.o(.text)
		beken378\func\key\multi_button.o(.text)
		beken378\func\key_handle\key_handle.o(.text)
		beken378\func\lwip_intf\platform_stub.o(.text)
		beken378\func\lwip_intf\tcp_server.o(.text)
		beken378\func\lwip_intf\dhcpd\dhcp-server-main.o(.text)
		beken378\func\lwip_intf\dhcpd\dhcp-server.o(.text)
		beken378\func\misc\fake_clock.o(.text)
		beken378\func\misc\pseudo_random.o(.text)
		beken378\func\misc\target_util.o(.text)
		beken378\func\music_player\app_music.o(.text)
		beken378\func\music_player\driver_audio_if.o(.text)
		beken378\func\music_player\fs_fat\disk_io.o(.text)
		beken378\func\music_player\fs_fat\ff.o(.text)
		beken378\func\music_player\fs_fat\ffsystem.o(.text)
		beken378\func\music_player\fs_fat\ffunicode.o(.text)
		beken378\func\music_player\fs_fat\playmode.o(.text)
		beken378\func\music_player\Mp3Lib\bitstream.o(.text)
		beken378\func\music_player\Mp3Lib\buffers.o(.text)
		beken378\func\music_player\Mp3Lib\dct32.o(.text)
		beken378\func\music_player\Mp3Lib\dequant.o(.text)
		beken378\func\music_player\Mp3Lib\dqchan.o(.text)
		beken378\func\music_player\Mp3Lib\huffman.o(.text)
		beken378\func\music_player\Mp3Lib\hufftabs.o(.text)
		beken378\func\music_player\Mp3Lib\imdct.o(.text)
		beken378\func\music_player\Mp3Lib\layer21.o(.text)
		beken378\func\music_player\Mp3Lib\mp3dec.o(.text)
		beken378\func\music_player\Mp3Lib\mp3tabs.o(.text)
		beken378\func\music_player\Mp3Lib\mp3_play.o(.text)
		beken378\func\music_player\Mp3Lib\scalfact.o(.text)
		beken378\func\music_player\Mp3Lib\stproc.o(.text)
		beken378\func\music_player\Mp3Lib\subband.o(.text)
		beken378\func\music_player\Mp3Lib\trigtabs.o(.text)
		beken378\func\net_param_intf\net_param.o(.text)
		beken378\func\power_save\manual_ps.o(.text)
		beken378\func\power_save\mcu_ps.o(.text)
		beken378\func\power_save\power_save.o(.text)
		beken378\func\rf_test\rx_sensitivity.o(.text)
		beken378\func\rf_test\tx_evm.o(.text)
		beken378\func\rwnx_intf\rw_ieee80211.o(.text)
		beken378\func\rwnx_intf\rw_msdu.o(.text)
		beken378\func\rwnx_intf\rw_msg_rx.o(.text)
		beken378\func\rwnx_intf\rw_msg_tx.o(.text)
		beken378\func\sdio_intf\sdio_intf.o(.text)
		beken378\func\sdio_trans\sdio_trans.o(.text)
		beken378\func\sd_music\sdcard_test.o(.text)
		beken378\func\sim_uart\gpio_uart.o(.text)
		beken378\func\sim_uart\pwm_uart.o(.text)
		beken378\func\spidma_intf\spidma_intf.o(.text)
		beken378\func\temp_detect\temp_detect.o(.text)
		beken378\func\uart_debug\cmd_evm.o(.text)
		beken378\func\uart_debug\cmd_help.o(.text)
		beken378\func\uart_debug\cmd_reg.o(.text)
		beken378\func\uart_debug\cmd_rx_sensitivity.o(.text)
		beken378\func\uart_debug\command_line.o(.text)
		beken378\func\uart_debug\command_table.o(.text)
		beken378\func\uart_debug\udebug.o(.text)
		beken378\func\udisk_mp3\ump3.o(.text)
		beken378\func\usb\fusb.o(.text)
		beken378\func\user_driver\BkDriverFlash.o(.text)
		beken378\func\user_driver\BkDriverGpio.o(.text)
		beken378\func\user_driver\BkDriverPwm.o(.text)
		beken378\func\user_driver\BkDriverUart.o(.text)
		beken378\func\user_driver\BkDriverWdg.o(.text)
		beken378\func\video_transfer\video_transfer.o(.text)
		beken378\func\wlan_ui\extral_cli.o(.text)
		beken378\func\wlan_ui\wlan_cli.o(.text)
		beken378\func\wlan_ui\wlan_ui.o(.text)
		beken378\func\func.o(.text.*)
		beken378\func\audio\audio_intf.o(.text.*)
		beken378\func\bk7011_cal\bk7011_cal.o(.text.*)
		beken378\func\bk7011_cal\bk7221u_cal.o(.text.*)
		beken378\func\bk7011_cal\bk7231U_cal.o(.text.*)
		beken378\func\bk7011_cal\bk7231_cal.o(.text.*)
		beken378\func\bk7011_cal\manual_cal_bk7231.o(.text.*)
		beken378\func\bk7011_cal\manual_cal_bk7231U.o(.text.*)
		beken378\func\camera_intf\camera_inft.o(.text.*)
		beken378\func\hostapd_intf\hostapd_intf.o(.text.*)
		beken378\func\joint_up\reconnect_startup.o(.text.*)
		beken378\func\joint_up\role_launch.o(.text.*)
		beken378\func\key\key_main.o(.text.*)
		beken378\func\key\multi_button.o(.text.*)
		beken378\func\key_handle\key_handle.o(.text.*)
		beken378\func\lwip_intf\platform_stub.o(.text.*)
		beken378\func\lwip_intf\tcp_server.o(.text.*)
		beken378\func\lwip_intf\dhcpd\dhcp-server-main.o(.text.*)
		beken378\func\lwip_intf\dhcpd\dhcp-server.o(.text.*)
		beken378\func\misc\fake_clock.o(.text.*)
		beken378\func\misc\pseudo_random.o(.text.*)
		beken378\func\misc\target_util.o(.text.*)
		beken378\func\music_player\app_music.o(.text.*)
		beken378\func\music_player\driver_audio_if.o(.text.*)
		beken378\func\music_player\fs_fat\disk_io.o(.text.*)
		beken378\func\music_player\fs_fat\ff.o(.text.*)
		beken378\func\music_player\fs_fat\ffsystem.o(.text.*)
		beken378\func\music_player\fs_fat\ffunicode.o(.text.*)
		beken378\func\music_player\fs_fat\playmode.o(.text.*)
		beken378\func\music_player\Mp3Lib\bitstream.o(.text.*)
		beken378\func\music_player\Mp3Lib\buffers.o(.text.*)
		beken378\func\music_player\Mp3Lib\dct32.o(.text.*)
		beken378\func\music_player\Mp3Lib\dequant.o(.text.*)
		beken378\func\music_player\Mp3Lib\dqchan.o(.text.*)
		beken378\func\music_player\Mp3Lib\huffman.o(.text.*)
		beken378\func\music_player\Mp3Lib\hufftabs.o(.text.*)
		beken378\func\music_player\Mp3Lib\imdct.o(.text.*)
		beken378\func\music_player\Mp3Lib\layer21.o(.text.*)
		beken378\func\music_player\Mp3Lib\mp3dec.o(.text.*)
		beken378\func\music_player\Mp3Lib\mp3tabs.o(.text.*)
		beken378\func\music_player\Mp3Lib\mp3_play.o(.text.*)
		beken378\func\music_player\Mp3Lib\scalfact.o(.text.*)
		beken378\func\music_player\Mp3Lib\stproc.o(.text.*)
		beken378\func\music_player\Mp3Lib\subband.o(.text.*)
		beken378\func\music_player\Mp3Lib\trigtabs.o(.text.*)
		beken378\func\net_param_intf\net_param.o(.text.*)
		beken378\func\power_save\manual_ps.o(.text.*)
		beken378\func\power_save\mcu_ps.o(.text.*)
		beken378\func\power_save\power_save.o(.text.*)
		beken378\func\rf_test\rx_sensitivity.o(.text.*)
		beken378\func\rf_test\tx_evm.o(.text.*)
		beken378\func\rwnx_intf\rw_ieee80211.o(.text.*)
		beken378\func\rwnx_intf\rw_msdu.o(.text.*)
		beken378\func\rwnx_intf\rw_msg_rx.o(.text.*)
		beken378\func\rwnx_intf\rw_msg_tx.o(.text.*)
		beken378\func\sdio_intf\sdio_intf.o(.text.*)
		beken378\func\sdio_trans\sdio_trans.o(.text.*)
		beken378\func\sd_music\sdcard_test.o(.text.*)
		beken378\func\sim_uart\gpio_uart.o(.text.*)
		beken378\func\sim_uart\pwm_uart.o(.text.*)
		beken378\func\spidma_intf\spidma_intf.o(.text.*)
		beken378\func\temp_detect\temp_detect.o(.text.*)
		beken378\func\uart_debug\cmd_evm.o(.text.*)
		beken378\func\uart_debug\cmd_help.o(.text.*)
		beken378\func\uart_debug\cmd_reg.o(.text.*)
		beken378\func\uart_debug\cmd_rx_sensitivity.o(.text.*)
		beken378\func\uart_debug\command_line.o(.text.*)
		beken378\func\uart_debug\command_table.o(.text.*)
		beken378\func\uart_debug\udebug.o(.text.*)
		beken378\func\udisk_mp3\ump3.o(.text.*)
		beken378\func\usb\fusb.o(.text.*)
		beken378\func\user_driver\BkDriverFlash.o(.text.*)
		beken378\func\user_driver\BkDriverGpio.o(.text.*)
		beken378\func\user_driver\BkDriverPwm.o(.text.*)
		beken378\func\user_driver\BkDriverUart.o(.text.*)
		beken378\func\user_driver\BkDriverWdg.o(.text.*)
		beken378\func\video_transfer\video_transfer.o(.text.*)
		beken378\func\wlan_ui\extral_cli.o(.text.*)
		beken378\func\wlan_ui\wlan_cli.o(.text.*)
		beken378\func\wlan_ui\wlan_ui.o(.text.*)
	} > flash
	
	. = ALIGN(0x8);
	.OTHERtext : 
	{		
		beken378\demo\ieee802_11_demo.o(.text)
		beken378\demo\ieee802_11_demo.o(.text.*)
	} > flash	

	. = ALIGN(0x8);
	.text : 
	{
	    *(.text)
	    *(.text.*)
	    *(.stub)
	    /* .gnu.warning sections are handled specially by elf32.em.  */
	    *(.gnu.warning)
	    *(.gnu.linkonce.t*)
	    *(.glue_7t) *(.glue_7)
	} > flash	

/* read only data.for example: const int rom_data[3]={1,2,3}; */
	.rodata ALIGN(8) : 
	{
		*(.rodata)
		*(.rodata.*)
		*(.gnu.linkonce.r*)
	} > flash
	
	.ARM.exidx :
	{
	    *(.ARM.exidx*)
	    *(.gnu.linkonce.armexidx.*)
	} > flash
	
/* globals.for example: int ram_data[3]={4,5,6}; */		/* VMA in RAM, but keep LMA in flash */
	_begin_data = .;
	.data : AT ( _begin_data )
	{
		*(.data .data.*)
		*(.sdata) 
		*(.gnu.linkonce.d*)
    	SORT(CONSTRUCTORS)
	} >ram
	
	/* Loader will copy data from _flash_begin to _ram_begin..ram_end */
	_data_flash_begin = LOADADDR(.data);
	_data_ram_begin = ADDR(.data);
	_data_ram_end = .;

/* uninitialized data section - global   int i; */
	.bss ALIGN(8):
	{
		_bss_start = .;
		*boot_handlers.O(.bss .bss.* .scommon .sbss .dynbss COMMON)
		*(.bss .bss.*)
		*(.scommon)
		*(.sbss)
		*(.dynbss)
		*(COMMON)
		/* Align here to ensure that the .bss section occupies space up to
		_end.  Align after .bss to ensure correct alignment even if the
		.bss section disappears because there are no input sections.  */
		. = ALIGN(32 / 8);
		_bss_end = .;
	} > ram						/* in RAM */

	. = ALIGN (8);
	_empty_ram = .;

/* This symbol defines end of code/data sections. Heap starts here. */
	PROVIDE(end    	  = .);
	
/* _stack symbol defines initial stack bottom addres. Stack grows to lower addresses.
   Typically you set this to be top of your RAM. Note: code never checks, if stack
   grows into heap area!
*/
	PROVIDE(_stack_unused      = 0x440000 - 0x3F0 - 0x7F0 - 0xFF0 - 0x3F0 - 0x10); /* 0x10*/
	PROVIDE(_stack_svc         = 0x440000 - 0x3F0 - 0x7F0 - 0xFF0 - 0x3F0); /* 0x3F0*/
	PROVIDE(_stack_irq         = 0x440000 - 0x3F0 - 0x7F0 - 0xFF0); /* 0xFF0*/
	PROVIDE(_stack_fiq         = 0x440000 - 0x3F0 - 0x7F0); /* 0x7F0*/
	PROVIDE(_stack_sys         = 0x440000 - 0x3F0); /* 0x3F0*/
}
 GROUP(
   libgcc.a
   libg.a
   libc.a
   libm.a
   libnosys.a
 )
